# ATtiny3227 device description
Architecture: AVR8X; Family: tinyAVR 2
Registers are 8-bit, read-write, reset 0x0 unless marked. A register's access mark holds for its fields unless they carry their own. Offsets are from the block's base; [hi:lo] are bit positions; {n}, {i} and the like mark numbered series.

## GPIO — General Purpose I/O Register
Instances: GPIO 0x001C
{0x0+i} GPIOR{i} reset not defined (i=0..3) — General Purpose IO Register {i}

## LOCKBIT
Instances: LOCKBIT 0x128A
0x00 LOCKBIT reset 0xC5 — Lock Bits
  [7:0] LB
    58=RWLOCK (Read and write lock); 197=NOLOCK (No locks)

## NVMCTRL — Non-volatile Memory Controller
Instances: NVMCTRL 0x1000
0x00 CTRLA — Control A
  [2:0] CMD — Command
    0=NONE (No Command); 1=PAGEWRITE (Write page); 2=PAGEERASE (Erase page); 3=PAGEERASEWRITE (Erase and write page); 4=PAGEBUFCLR (Page buffer clear); 5=CHIPERASE; 6=EEERASE (EEPROM erase); 7=FUSEWRITE (Write fuse (PDI only))
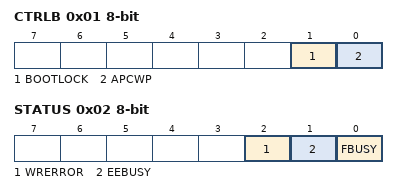
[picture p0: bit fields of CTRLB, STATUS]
0x01 CTRLB — Control B
  [1] BOOTLOCK
  [0] APCWP — Application code write protect
0x02 STATUS ro
  [2] WRERROR — Write error
  [1] EEBUSY — EEPROM busy
  [0] FBUSY — Flash busy
0x03 INTCTRL — Interrupt Control
  [0] EEREADY — EEPROM Ready
0x04 INTFLAGS — Interrupt Flags
  [0] EEREADY — EEPROM Ready
0x06 DATA 16-bit reset not defined
0x08 ADDR 16-bit reset not defined — Address

## PORT — I/O Ports
Instances: PORTA 0x0400, PORTB 0x0420, PORTC 0x0440
0x00 DIR reset not defined — Data Direction
0x01 DIRSET reset not defined — Data Direction Set
0x02 DIRCLR reset not defined — Data Direction Clear
0x03 DIRTGL reset not defined — Data Direction Toggle
0x04 OUT reset not defined — Output Value
0x05 OUTSET reset not defined — Output Value Set
0x06 OUTCLR reset not defined — Output Value Clear
0x07 OUTTGL reset not defined — Output Value Toggle
0x08 IN reset not defined — Input Value
0x09 INTFLAGS — Interrupt Flags
  [7:0] INT — Pin Interrupt
0x0A PORTCTRL — Port Control
  [0] SRL — Slew Rate Limit Enable
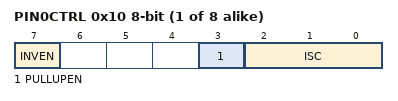
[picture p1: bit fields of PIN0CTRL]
{0x10+i} PIN{i}CTRL (i=0..7) — Pin {i} Control
  [7] INVEN — Inverted I/O Enable
  [3] PULLUPEN — Pullup enable
  [2:0] ISC — Input/Sense Configuration
    0=INTDISABLE (Interrupt disabled but input buffer enabled); 1=BOTHEDGES (Sense Both Edges); 2=RISING (Sense Rising Edge); 3=FALLING (Sense Falling Edge); 4=INPUT_DISABLE (Digital Input Buffer disabled); 5=LEVEL (Sense low Level)

## PORTMUX — Port Multiplexer
Instances: PORTMUX 0x05E0
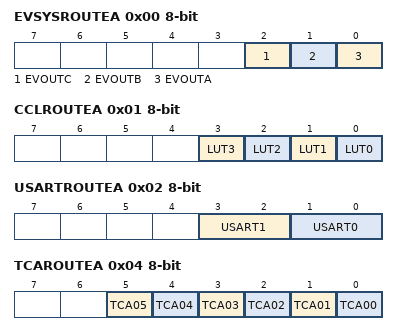
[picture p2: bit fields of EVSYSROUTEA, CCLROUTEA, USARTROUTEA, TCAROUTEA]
0x00 EVSYSROUTEA — Port Multiplexer EVSYS
  [2] EVOUTC — Event Output C
    0=DEFAULT (EVOUT on PC2)
  [1] EVOUTB — Event Output B
    0=DEFAULT (EVOUT on PB2); 1=ALT1 (EVOUT on PB7)
  [0] EVOUTA — Event Output A
    0=DEFAULT (EVOUT on PA2); 1=ALT1 (EVOUT on PA7)
0x01 CCLROUTEA — Port Multiplexer CCL
  [3] LUT3 — CCL LUT3
    0=DEFAULT (Out: PC4 In: PC0, PC1, PC2); 1=ALT1 (Out: PA5 In: PC0, PC1, PC2)
  [2] LUT2 — CCL LUT2
    0=DEFAULT (Out: PB3 In: PB0, PB1, PB2); 1=ALT1 (Out: PB6 In: PB0, PB1, PB2)
  [1] LUT1 — CCL LUT1
    0=DEFAULT (Out: PA7 In: PC3, PC4, PC5); 1=ALT1 (Out: PC1 In: PC3, PC4, PC5)
  [0] LUT0 — CCL LUT0
    0=DEFAULT (Out: PA4 In: PA0, PA1, PA2); 1=ALT1 (Out: PB4 In: PA0, PA1, PA2)
0x02 USARTROUTEA — Port Multiplexer USART register A
  [3:2] USART1 — Port Multiplexer USART1
    0=DEFAULT (USART1 on PA[4:1]); 3=NONE (Not connected to any pins); 1=ALT1 (USART1 on PC[3:0])
  [1:0] USART0 — Port Multiplexer USART0
    0=DEFAULT (USART0 on PB[3:0]); 1=ALT1 (USART0 on PA[4:1]); 3=NONE (Not connected to any pins)
0x03 SPIROUTEA — Port Multiplexer TWI and SPI
  [1:0] SPI0 — Port Multiplexer SPI0
    0=DEFAULT (PA0, PA1, PA2, PA3); 3=NONE (Not connected to any pins); 1=ALT1 (PC2, PC1, PC0, PC3)
0x04 TCAROUTEA — Port Multiplexer TCA
  [5] TCA05 — Port Multiplexer TCA0 Output 5
    0=DEFAULT (WO5 on PA5); 1=ALT1 (WO5 on PC5)
  [4] TCA04 — Port Multiplexer TCA0 Output 4
    0=DEFAULT (WO4 on PA4); 1=ALT1 (WO4 on PC4)
  [3] TCA03 — Port Multiplexer TCA0 Output 3
    0=DEFAULT (WO3 on PA3); 1=ALT1 (WO3 on PC3)
  [2] TCA02 — Port Multiplexer TCA0 Output 2
    0=DEFAULT (WO2 on PB2); 1=ALT1 (WO2 on PB5)
  [1] TCA01 — Port Multiplexer TCA0 Output 1
    0=DEFAULT (WO1 on PB1); 1=ALT1 (WO1 on PB4)
  [0] TCA00 — Port Multiplexer TCA0 Output 0
    0=DEFAULT (WO0 on PB0); 1=ALT1 (WO0 on PB3)
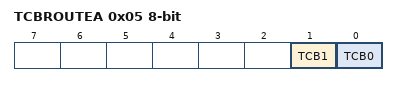
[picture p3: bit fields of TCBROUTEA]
0x05 TCBROUTEA — Port Multiplexer TCB
  [1] TCB1 — Port Multiplexer TCB1
    0=DEFAULT (WO on PA3); 1=ALT1 (WO on PC4)
  [0] TCB0 — Port Multiplexer TCB0
    0=DEFAULT (WO on PA5); 1=ALT1 (WO on PC0)
